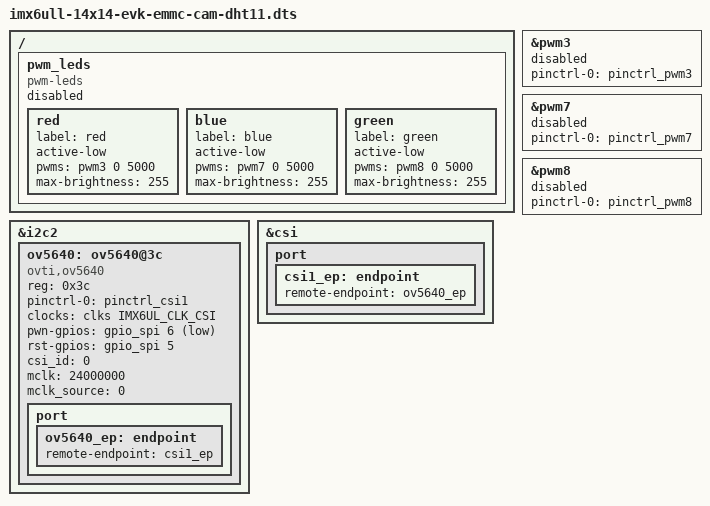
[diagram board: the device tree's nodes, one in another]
/*
 * Copyright (C) 2016 Freescale Semiconductor, Inc.
 *
 * This program is free software; you can redistribute it and/or modify
 * it under the terms of the GNU General Public License version 2 as
 * published by the Free Software Foundation.
 */

#include "imx6ull-14x14-evk-emmc.dts"

/ {
	pwm_leds{
		compatible = "pwm-leds";
		status = "disable";

		red {
			label = "red";
			active-low;
			pwms = <&pwm3 0 5000>;
			max-brightness = <255>;
		};

		blue {
			label =  "blue";
			active-low;
			pwms = <&pwm7 0 5000>;
			max-brightness = <255>;
		};

		green {
			label = "green";
			active-low;
			pwms = <&pwm8 0 5000>;
			max-brightness = <255>;
		};
	};

};

&pwm3 {
	pinctrl-names = "default";
	pinctrl-0 = <&pinctrl_pwm3>;
	status = "disable";
};

&pwm7 {
	pinctrl-names = "default";
	pinctrl-0 = <&pinctrl_pwm7>;
	status = "disable";
};

&pwm8 {
	pinctrl-names = "default";
	pinctrl-0 = <&pinctrl_pwm8>;
	status = "disable";
};

&i2c2 {
	ov5640: ov5640@3c {
		compatible = "ovti,ov5640";
		reg = <0x3c>;
		pinctrl-names = "default";
		pinctrl-0 = <&pinctrl_csi1>;
		clocks = <&clks IMX6UL_CLK_CSI>;
		clock-names = "csi_mclk";
		pwn-gpios = <&gpio_spi 6 1>;
		rst-gpios = <&gpio_spi 5 0>;
		csi_id = <0>;
		mclk = <24000000>;
		mclk_source = <0>;
		status = "okay";    /* 摄像头使能 */
		port {
			ov5640_ep: endpoint {
				remote-endpoint = <&csi1_ep>;
			};
		};
	};
};

&csi {
	status = "okay";  /* 摄像头总线使能 */

	port {
		csi1_ep: endpoint {
			remote-endpoint = <&ov5640_ep>;
		};
	};
};



